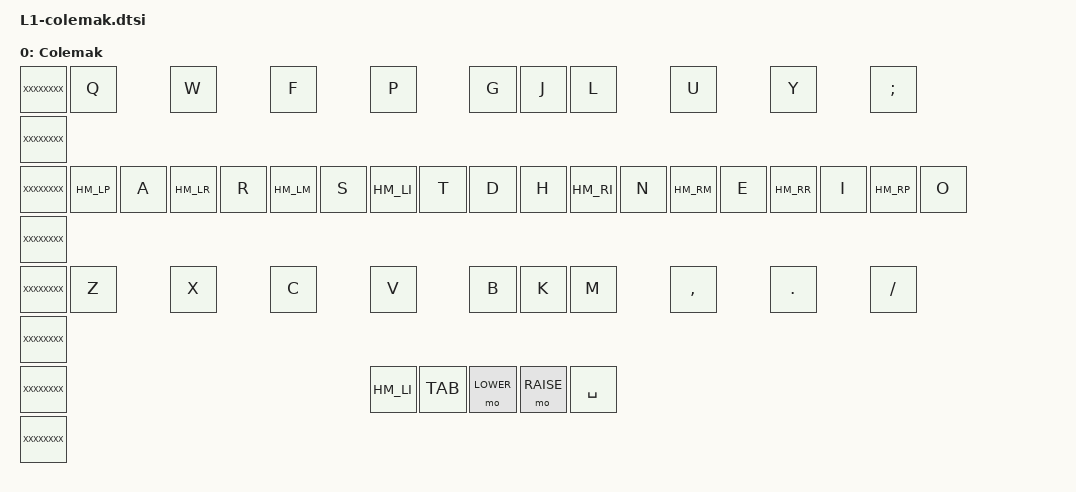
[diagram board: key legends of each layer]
/**
 *
 */

/ {
  keymap {
    compatible = "zmk,keymap";

    colemak_layer {
        label = "Colemak";
        bindings = <
//					╭───────────────┬───────────────┬───────────────┬───────────────┬───────────────╮   ╭───────────────┬───────────────┬───────────────┬───────────────┬───────────────╮
//  0               	1               2               3               4               5                   6               7               8               9               10
	XXXXXXXX			&kp Q           &kp W           &kp F           &kp P           &kp G               &kp J           &kp L           &kp U           &kp Y           &kp SEMI
	XXXXXXXX	//	├───────────────┼───────────────┼───────────────┼───────────────┼───────────────┤   ├───────────────├───────────────┼───────────────┼───────────────┼───────────────┤
//  12					13              14              15              16              17                  18              19              20              21              22
	XXXXXXXX			HM_LP A      	HM_LR R      	HM_LM S      	HM_LI T      	&kp D               &kp H           HM_RI N     	HM_RM E   		HM_RR I      	HM_RP O
	XXXXXXXX	//	├───────────────┼───────────────┼───────────────┼───────────────┼───────────────┤   ├───────────────├───────────────┼───────────────┼───────────────┼───────────────┤
//  24					25              26              27              28              29                  30              31              32              33              34
	XXXXXXXX			&kp Z     		&kp X      		&kp C      		&kp V       	&kp B               &kp K           &kp M       	&kp COMMA  		&kp DOT   		&kp FSLH
	XXXXXXXX	//	╰───────────────┴───────────────┼───────────────┼───────────────┼───────────────┤   ├───────────────├───────────────┼───────────────┼───────────────┴───────────────╯
//	36              													37              38                  39              40
	XXXXXXXX       														HM_LI TAB		&mo LOWER			&mo RAISE		&kp SPACE
//                                                                  ╰───────────────┴───────────────╯   ╰───────────────┴───────────────╯
	XXXXXXXX
			>;
		};
    };
};
